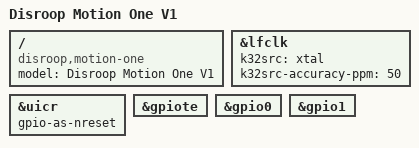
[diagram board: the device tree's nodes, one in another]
/* Disroop Motion One V1: nRF52840 im Ebyte E73-2G4M08S1C, IMU ICM-45686 an SPI.
 * ALLE Pins stehen in motion_one-pins.dtsi (aus electronics/PINOUT_V1.json r1). */
/dts-v1/;
#include <nordic/nrf52840_qiaa.dtsi>
#include <nordic/nrf52840_partition_uf2_sdv6.dtsi>
#include <zephyr/dt-bindings/input/input-event-codes.h>
#include <zephyr/dt-bindings/pwm/pwm.h>
#include <zephyr/dt-bindings/adc/nrf-saadc.h>
#include <zephyr/dt-bindings/gpio/gpio.h>

/ {
	model = "Disroop Motion One V1";
	compatible = "disroop,motion-one";

};

/* PINOUT_V1: 32.768-kHz-Quarz an XL1/XL2 -> LFXO. Genauigkeit ANNAHME 50 ppm (Quarz-Datenblatt offen).
 * DCDC-Bauteile im E73 unbekannt -> LDO (Default). */
&lfclk {
	k32src = "xtal";
	k32src-accuracy-ppm = <50>;
};

&uicr {
	gpio-as-nreset;
};

&gpiote {
	status = "okay";
};

&gpio0 {
	status = "okay";
};

&gpio1 {
	status = "okay";
};

#include "motion_one-pins.dtsi"
